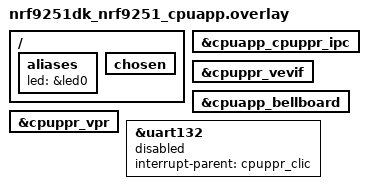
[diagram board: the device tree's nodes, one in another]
/*
 * Copyright (c) 2026 Nordic Semiconductor ASA
 *
 * SPDX-License-Identifier: LicenseRef-Nordic-5-Clause
 */

/ {
	aliases {
		led = &led0;
	};
};

ipc0: &cpuapp_cpuppr_ipc {
	status = "okay";
};

&cpuppr_vevif {
	status = "okay";
};

&cpuapp_bellboard {
	status = "okay";
};

/ {
	chosen {
		/delete-property/ zephyr,bt-hci;
	};
};

&cpuppr_vpr {
	status = "okay";
};

&uart132 {
	status = "reserved";
	interrupt-parent = <&cpuppr_clic>;
};
